# STM32L452xx register map
File version: 1.0
Registers are 32-bit, access not given, reset 0x0 unless marked. A register's access mark holds for its fields unless they carry their own. Offsets are from the block's base; [hi:lo] are bit positions; {n}, {i} and the like mark numbered series.

## OPAMP1
Base 0x40007800
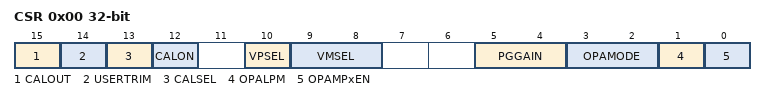
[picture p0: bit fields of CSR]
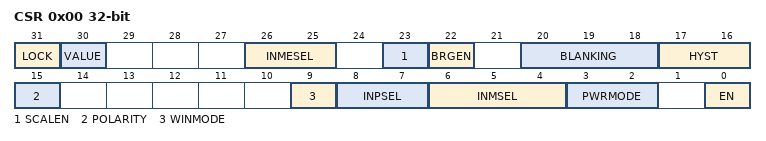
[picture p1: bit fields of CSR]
0x00 CSR
  [15] CALOUT, [14] USERTRIM, [13] CALSEL, [12] CALON, [10] VPSEL, [9:8] VMSEL, [12:8] TRIMOFFSETP, [12:8] TRIMLPOFFSETP, [5:4] PGGAIN, [3:2] OPAMODE, [1] OPALPM, [0] OPAMPxEN, [4:0] TRIMOFFSETN, [4:0] TRIMLPOFFSETN
0x04 OTR
0x08 LPOTR

## OPAMP1_COMMON
Base 0x40007800
0x00 CSR
  [15] CALOUT, [14] USERTRIM, [13] CALSEL, [12] CALON, [10] VPSEL, [9:8] VMSEL, [5:4] PGGAIN, [3:2] OPAMODE, [1] OPALPM, [0] OPAMPxEN

## LPTIM1
Base 0x40007C00
Same registers: LPTIM2 0x40009400
0x00 ISR
  [24] ENC, [23] COUNTMODE, [22] PRELOAD, [21] WAVPOL, [20] WAVE, [19] TIMOUT, [18:17] TRIGEN, [15:13] TRIGSEL, [11:9] PRESC, [6] DOWN, [6] DOWNCF, [6] DOWNIE, [7:6] TRGFLT, [5] UP, [5] UPCF, [5] UPIE, [4] ARROK, [4] ARROKCF, [4] ARROKIE, [3] CMPOK, [3] CMPOKCF, [3] CMPOKIE, [4:3] CKFLT, [2] EXTTRIG, [2] EXTTRIGCF, [2] EXTTRIGIE, [2] CNTSTRT, [1] ARRM, [1] ARRMCF, [1] ARRMIE, [2:1] CKPOL, [1] SNGSTRT, [0] CMPM, [0] CMPMCF, [0] CMPMIE, [0] CKSEL, [0] ENABLE, [15:0] CMP, [15:0] ARR, [15:0] CNT, [1:0] OR
0x04 ICR
0x08 IER
0x0C CFGR
0x10 CR
0x14 CMP
0x18 ARR
0x1C CNT
0x20 OR

## SYSCFG
Base 0x40010000
0x00 MEMRMP
  [n] PAGE{n} (n=0..31), [n+19] I2C{n}_FMP (n=1..4), [n+10] I2C_PB{n}_FMP (n=6..9), [4n+2:4n] EXTI{n} (n=0..3), [4n-14:4n-16] EXTI{n} (n=4..7), [4n-30:4n-32] EXTI{n} (n=8..11), [4n-46:4n-48] EXTI{n} (n=12..15), [8] BOOSTEN, [8] SPF, [3] ECCL, [2] PVDL, [1] SRAM2BSY, [1] SPL, [2:0] MEM_MODE, [0] FWDIS, [0] SRAM2ER, [0] CLL, [7:0] KEY
0x04 CFGR1
0x08 EXTICR.0
0x0C EXTICR.1
0x10 EXTICR.2
0x14 EXTICR.3
0x18 SCSR
0x1C CFGR2
0x20 SWPR
0x24 SKR

## VREFBUF
Base 0x40010030
0x00 CSR
  [3] VRR, [2] VRS, [1] HIZ, [0] ENVR, [5:0] TRIM
0x04 CCR

## COMP1
Base 0x40010200
Same registers: COMP2 0x40010204, COMP12_COMMON 0x40010204
0x00 CSR
  [31] LOCK, [30] VALUE, [26:25] INMESEL, [23] SCALEN, [22] BRGEN, [20:18] BLANKING, [17:16] HYST, [15] POLARITY, [9] WINMODE, [8:7] INPSEL, [6:4] INMSEL, [3:2] PWRMODE, [0] EN

## EXTI
Base 0x40010400
0x00 IMR1
  [31] IM31, [31] EM31, [n] IM{n} (n=0..29), [n] EM{n} (n=0..29), [n] RT{n} (n=18..22), [n] FT{n} (n=18..22), [n] SWI{n} (n=18..22), [n] PIF{n} (n=18..22), [n] RT{n} (n=0..16), [n] FT{n} (n=0..16), [n] SWI{n} (n=0..16), [n] PIF{n} (n=0..16), [8] IM40, [8] EM40, [6] IM38, [6] EM38, [6] RT38, [6] FT38, [6] SWI38, [6] PIF38, [5] IM37, [5] EM37, [5] RT37, [5] FT37, [5] SWI37, [5] PIF37, [3] IM35, [3] EM35, [3] RT35, [3] FT35, [3] SWI35, [3] PIF35, [1] IM33, [1] EM33, [0] IM32, [0] EM32
0x04 EMR1
0x08 RTSR1
0x0C FTSR1
0x10 SWIER1
0x14 PR1
0x20 IMR2
0x24 EMR2
0x28 RTSR2
0x2C FTSR2
0x30 SWIER2
0x34 PR2

## FIREWALL
Base 0x40011C00
0x00 CSSA
0x04 CSL
0x08 NVDSSA
0x0C NVDSL
0x10 VDSSA
0x14 VDSL
0x20 CR

## SDMMC1
Base 0x40012800
0x00 POWER
  [22] SDIOIT, [22] SDIOITC, [22] SDIOITIE, [21] RXDAVL, [21] RXDAVLIE, [20] TXDAVL, [20] TXDAVLIE, [19] RXFIFOE, [19] RXFIFOEIE, [18] TXFIFOE, [18] TXFIFOEIE, [17] RXFIFOF, [17] RXFIFOFIE, [16] TXFIFOF, [16] TXFIFOFIE, [15] RXFIFOHF, [15] RXFIFOHFIE, [14] HWFC_EN, [14] TXFIFOHE, [14] TXFIFOHEIE, [13] NEGEDGE, [13] RXACT, [13] RXACTIE, [12] TXACT, [12] TXACTIE, [12:11] WIDBUS, [11] SDIOSUSPEND, [11] SDIOEN, [11] CMDACT, [11] CMDACTIE, [10] BYPASS, [10] CPSMEN, [10] RWMOD, [10] DBCKEND, [10] DBCKENDC, [10] DBCKENDIE, [9] PWRSAV, [9] WAITPEND, [9] RWSTOP, [9] STBITERR, [9] STBITERRC, [8] CLKEN, [8] WAITINT, [8] RWSTART, [8] DATAEND, [8] DATAENDC, [8] DATAENDIE, [7] CMDSENT, [7] CMDSENTC, [7] CMDSENTIE, [7:6] WAITRESP, [6] CMDREND, [6] CMDRENDC, [6] CMDRENDIE, [5] RXOVERR, [5] RXOVERRC, [5] RXOVERRIE, [7:4] DBLOCKSIZE, [4] TXUNDERR, [4] TXUNDERRC, [4] TXUNDERRIE, [3] DMAEN, [3] DTIMEOUT, [3] DTIMEOUTC, [3] DTIMEOUTIE, [2] DTMODE, [2] CTIMEOUT, [2] CTIMEOUTC, [2] CTIMEOUTIE, [1] DTDIR, [1] DCRCFAIL, [1] DCRCFAILC, [1] DCRCFAILIE, [1:0] PWRCTRL, [7:0] CLKDIV, [31:0] CMDARG, [5:0] CMDINDEX, [5:0] RESPCMD, [31:0] CARDSTATUS{n} (n=1..4), [31:0] DATATIME, [24:0] DATALENGTH, [0] DTEN, [24:0] DATACOUNT, [0] CCRCFAIL, [0] CCRCFAILC, [0] CCRCFAILIE, [23:0] FIFOCOUNT, [31:0] FIFODATA
0x04 CLKCR
0x08 ARG
0x0C CMD
0x10 RESPCMD
{0x10+4i} RESP{i} (i=1..4)
0x24 DTIMER
0x28 DLEN
0x2C DCTRL
0x30 DCOUNT
0x34 STA
0x38 ICR
0x3C MASK
0x48 FIFOCNT
0x80 FIFO
